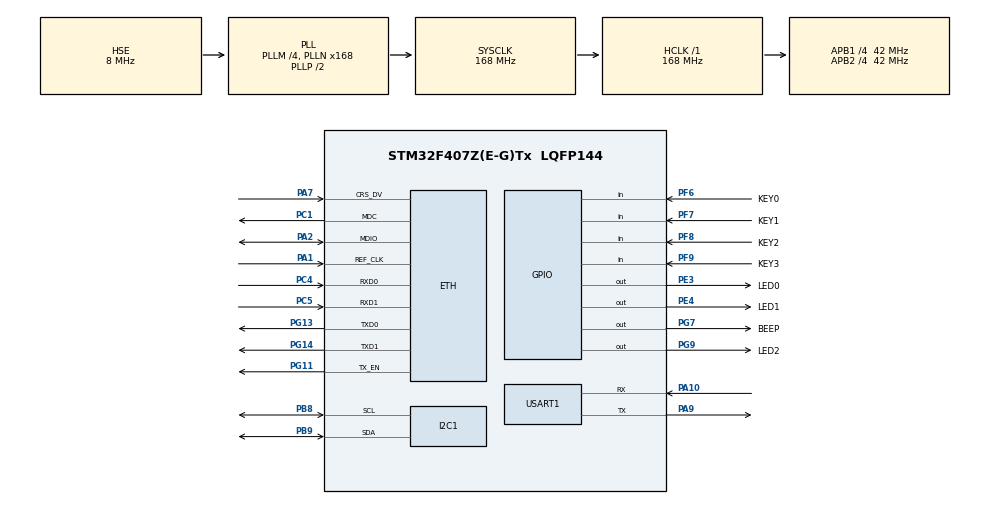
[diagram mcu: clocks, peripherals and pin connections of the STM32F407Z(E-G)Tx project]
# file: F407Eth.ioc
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Dma.Request0=USART1_RX
Dma.USART1_RX.0.Direction=DMA_PERIPH_TO_MEMORY
Dma.USART1_RX.0.FIFOMode=DMA_FIFOMODE_DISABLE
Dma.USART1_RX.0.Instance=DMA2_Stream2
Dma.USART1_RX.0.MemDataAlignment=DMA_MDATAALIGN_BYTE
Dma.USART1_RX.0.MemInc=DMA_MINC_ENABLE
Dma.USART1_RX.0.Mode=DMA_NORMAL
Dma.USART1_RX.0.PeriphDataAlignment=DMA_PDATAALIGN_BYTE
Dma.USART1_RX.0.PeriphInc=DMA_PINC_DISABLE
Dma.USART1_RX.0.Priority=DMA_PRIORITY_LOW
ETH.MediaInterface=ETH_MEDIA_INTERFACE_RMII
ETH.PHY_Name_RMII=userPHY
ETH.PHY_User_Name=DP83848
FREERTOS.Queues01=ethMsgQueue,16,ETH_MSG,0,Dynamic,NULL,NULL
FREERTOS.Tasks01=defaultTask,24,512,StartDefaultTask,Default,NULL,Dynamic,NULL,NULL;ethTask,8,512,StartEthTask,As weak,NULL,Dynamic,NULL,NULL;usart1Task,8,512,StartUsart1Task,As weak,NULL,Dynamic,NULL,NULL;serverTask,8,1024,StartServerTask,As weak,NULL,Dynamic,NULL,NULL
FREERTOS.configTOTAL_HEAP_SIZE=20480
LWIP.GATEWAY_ADDRESS=192.168.000.001
LWIP.IP_ADDRESS=192.168.000.111
LWIP.LWIP_DHCP=0
LWIP.LWIP_HTTPD=0
LWIP.MEMP_NUM_PBUF=40
LWIP.MEMP_NUM_TCP_SEG=800
LWIP.MEM_SIZE=15360
LWIP.NETMASK_ADDRESS=255.255.255.000
LWIP.PBUF_POOL_BUFSIZE=564
LWIP.PBUF_POOL_SIZE=40
LWIP.TCP_MSS=1024
LWIP.TCP_QUEUE_OOSEQ=0
LWIP.TCP_SND_BUF=15360
LWIP.TCP_SND_QUEUELEN=400
LWIP.TCP_WND=4096
LWIP.Version=v2.0.3_Cube
Mcu.Family=STM32F4
Mcu.Name=STM32F407Z(E-G)Tx
Mcu.Package=LQFP144
NVIC.DMA2_Stream2_IRQn=true\:5\:0\:false\:false\:true\:true\:false\:true
NVIC.ETH_IRQn=true\:5\:0\:false\:false\:true\:true\:true\:true
NVIC.PriorityGroup=NVIC_PRIORITYGROUP_4
NVIC.TIM1_UP_TIM10_IRQn=true\:0\:0\:false\:false\:true\:false\:false\:true
NVIC.TimeBase=TIM1_UP_TIM10_IRQn
NVIC.TimeBaseIP=TIM1
NVIC.USART1_IRQn=true\:5\:0\:false\:false\:true\:true\:true\:true
PA1.Mode=RMII
PA1.Signal=ETH_REF_CLK
PA10.Mode=Asynchronous
PA10.Signal=USART1_RX
PA13.Mode=JTAG_5_pins
PA13.Signal=SYS_JTMS-SWDIO
PA14.Mode=JTAG_5_pins
PA14.Signal=SYS_JTCK-SWCLK
PA15.Mode=JTAG_5_pins
PA15.Signal=SYS_JTDI
PA2.Mode=RMII
PA2.Signal=ETH_MDIO
PA7.Mode=RMII
PA7.Signal=ETH_CRS_DV
PA9.Mode=Asynchronous
PA9.Signal=USART1_TX
PB12.Signal=CAN2_RX
PB13.Signal=CAN2_TX
PB3.Mode=JTAG_5_pins
PB3.Signal=SYS_JTDO-SWO
PB4.Mode=JTAG_5_pins
PB4.Signal=SYS_JTRST
PB8.Mode=I2C
PB8.Signal=I2C1_SCL
PB9.Mode=I2C
PB9.Signal=I2C1_SDA
PC1.Mode=RMII
PC1.Signal=ETH_MDC
PC14-OSC32_IN.Mode=LSE-External-Oscillator
PC14-OSC32_IN.Signal=RCC_OSC32_IN
PC15-OSC32_OUT.Mode=LSE-External-Oscillator
PC15-OSC32_OUT.Signal=RCC_OSC32_OUT
PC4.Mode=RMII
PC4.Signal=ETH_RXD0
PC5.Mode=RMII
PC5.Signal=ETH_RXD1
PE3.GPIO_Label=LED0
PE3.GPIO_Speed=GPIO_SPEED_FREQ_HIGH
PE3.PinState=GPIO_PIN_SET
PE3.Signal=GPIO_Output
PE4.GPIO_Label=LED1
PE4.GPIO_Speed=GPIO_SPEED_FREQ_HIGH
PE4.PinState=GPIO_PIN_SET
PE4.Signal=GPIO_Output
PF6.GPIO_Label=KEY0
PF6.GPIO_PuPd=GPIO_PULLUP
PF6.Signal=GPIO_Input
PF7.GPIO_Label=KEY1
PF7.GPIO_PuPd=GPIO_PULLUP
PF7.Signal=GPIO_Input
PF8.GPIO_Label=KEY2
PF8.GPIO_PuPd=GPIO_PULLUP
PF8.Signal=GPIO_Input
PF9.GPIO_Label=KEY3
PF9.GPIO_PuPd=GPIO_PULLUP
PF9.Signal=GPIO_Input
PG11.Mode=RMII
PG11.Signal=ETH_TX_EN
PG13.Mode=RMII
PG13.Signal=ETH_TXD0
PG14.Mode=RMII
PG14.Signal=ETH_TXD1
PG7.GPIO_Label=BEEP
PG7.Signal=GPIO_Output
PG9.GPIO_Label=LED2
PG9.GPIO_Speed=GPIO_SPEED_FREQ_HIGH
PG9.PinState=GPIO_PIN_SET
PG9.Signal=GPIO_Output
PH0-OSC_IN.Mode=HSE-External-Oscillator
PH0-OSC_IN.Signal=RCC_OSC_IN
PH1-OSC_OUT.Mode=HSE-External-Oscillator
PH1-OSC_OUT.Signal=RCC_OSC_OUT
ProjectManager.HeapSize=0x200
ProjectManager.StackSize=0x400
ProjectManager.TargetToolchain=STM32CubeIDE
RCC.48MHZClocksFreq_Value=84000000
RCC.AHBFreq_Value=168000000
RCC.APB1CLKDivider=RCC_HCLK_DIV4
RCC.APB1Freq_Value=42000000
RCC.APB1TimFreq_Value=84000000
RCC.APB2CLKDivider=RCC_HCLK_DIV4
RCC.APB2Freq_Value=42000000
RCC.APB2TimFreq_Value=84000000
RCC.CortexFreq_Value=168000000
RCC.HCLKFreq_Value=168000000
RCC.HSE_VALUE=8000000
RCC.HSI_VALUE=16000000
RCC.PLLM=4
RCC.PLLN=168
RCC.PLLSourceVirtual=RCC_PLLSOURCE_HSE
RCC.SYSCLKFreq_VALUE=168000000
RCC.SYSCLKSource=RCC_SYSCLKSOURCE_PLLCLK
RCC.VCOOutputFreq_Value=336000000
USART1.VirtualMode=VM_ASYNC
VP_FREERTOS_VS_CMSIS_V2.Mode=CMSIS_V2
VP_LWIP_VS_Enabled.Mode=Enabled
VP_SYS_VS_tim1.Mode=TIM1
board=custom

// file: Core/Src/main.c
/* USER CODE BEGIN Header */
/**
  ******************************************************************************
  * @file           : main.c
  * @brief          : Main program body
  ******************************************************************************
  * @attention
  *
  * <h2><center>&copy; Copyright (c) 2020 STMicroelectronics.
  * All rights reserved.</center></h2>
  *
  * This software component is licensed by ST under BSD 3-Clause license,
  * the "License"; You may not use this file except in compliance with the
  * License. You may obtain a copy of the License at:
  *                        opensource.org/licenses/BSD-3-Clause
  *
  ******************************************************************************
  */
/* USER CODE END Header */

#include "main.h"
#include "cmsis_os.h"
#include "dma.h"
#include "i2c.h"
#include "lwip.h"
#include "usart.h"
#include "gpio.h"

/* USER CODE BEGIN Includes */
#include "TaskApp.h"

/* USER CODE END Includes */

void SystemClock_Config(void);
void MX_FREERTOS_Init(void);

int main(void)
{

  /* MCU Configuration--------------------------------------------------------*/

  /* Reset of all peripherals, Initializes the Flash interface and the Systick. */
  HAL_Init();

  /* Configure the system clock */
  SystemClock_Config();

  /* Initialize all configured peripherals */
  MX_GPIO_Init();
  MX_DMA_Init();
  MX_I2C1_Init();
  MX_USART1_UART_Init();
  MX_LWIP_Init();
  /* USER CODE BEGIN 2 */
  InitMyApp();
  /* USER CODE END 2 */
  /* Init scheduler */
  osKernelInitialize();

  /* Call init function for freertos objects (in freertos.c) */
  MX_FREERTOS_Init();

  /* Start scheduler */
  osKernelStart();

  /* We should never get here as control is now taken by the scheduler */

  /* Infinite loop */
  while (1)
  {

  }
}

void SystemClock_Config(void)
{
  RCC_OscInitTypeDef RCC_OscInitStruct = {0};
  RCC_ClkInitTypeDef RCC_ClkInitStruct = {0};

  /** Configure the main internal regulator output voltage
  */
  __HAL_RCC_PWR_CLK_ENABLE();
  __HAL_PWR_VOLTAGESCALING_CONFIG(PWR_REGULATOR_VOLTAGE_SCALE1);
  /** Initializes the CPU, AHB and APB busses clocks
  */
  RCC_OscInitStruct.OscillatorType = RCC_OSCILLATORTYPE_HSE;
  RCC_OscInitStruct.HSEState = RCC_HSE_ON;
  RCC_OscInitStruct.PLL.PLLState = RCC_PLL_ON;
  RCC_OscInitStruct.PLL.PLLSource = RCC_PLLSOURCE_HSE;
  RCC_OscInitStruct.PLL.PLLM = 4;
  RCC_OscInitStruct.PLL.PLLN = 168;
  RCC_OscInitStruct.PLL.PLLP = RCC_PLLP_DIV2;
  RCC_OscInitStruct.PLL.PLLQ = 4;
  if (HAL_RCC_OscConfig(&RCC_OscInitStruct) != HAL_OK)
  {
    Error_Handler();
  }
  /** Initializes the CPU, AHB and APB busses clocks
  */
  RCC_ClkInitStruct.ClockType = RCC_CLOCKTYPE_HCLK|RCC_CLOCKTYPE_SYSCLK
                              |RCC_CLOCKTYPE_PCLK1|RCC_CLOCKTYPE_PCLK2;
  RCC_ClkInitStruct.SYSCLKSource = RCC_SYSCLKSOURCE_PLLCLK;
  RCC_ClkInitStruct.AHBCLKDivider = RCC_SYSCLK_DIV1;
  RCC_ClkInitStruct.APB1CLKDivider = RCC_HCLK_DIV4;
  RCC_ClkInitStruct.APB2CLKDivider = RCC_HCLK_DIV4;

  if (HAL_RCC_ClockConfig(&RCC_ClkInitStruct, FLASH_LATENCY_5) != HAL_OK)
  {
    Error_Handler();
  }
}

void HAL_TIM_PeriodElapsedCallback(TIM_HandleTypeDef *htim)
{
  if (htim->Instance == TIM1) {
    HAL_IncTick();
  }
}

void Error_Handler(void)
{
}

/************************ (C) COPYRIGHT STMicroelectronics *****END OF FILE****/

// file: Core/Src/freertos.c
/* USER CODE BEGIN Header */
/**
  ******************************************************************************
  * File Name          : freertos.c
  * Description        : Code for freertos applications
  ******************************************************************************
  * @attention
  *
  * <h2><center>&copy; Copyright (c) 2020 STMicroelectronics.
  * All rights reserved.</center></h2>
  *
  * This software component is licensed by ST under Ultimate Liberty license
  * SLA0044, the "License"; You may not use this file except in compliance with
  * the License. You may obtain a copy of the License at:
  *                             www.st.com/SLA0044
  *
  ******************************************************************************
  */
/* USER CODE END Header */

#include "FreeRTOS.h"
#include "task.h"
#include "main.h"
#include "cmsis_os.h"

/* USER CODE BEGIN Includes */
#include "TaskApp.h"

/* USER CODE END Includes */

/* Definitions for defaultTask */
osThreadId_t defaultTaskHandle;
const osThreadAttr_t defaultTask_attributes = {
  .name = "defaultTask",
  .priority = (osPriority_t) osPriorityNormal,
  .stack_size = 512
};
/* Definitions for ethTask */
osThreadId_t ethTaskHandle;
const osThreadAttr_t ethTask_attributes = {
  .name = "ethTask",
  .priority = (osPriority_t) osPriorityLow,
  .stack_size = 512
};
/* Definitions for usart1Task */
osThreadId_t usart1TaskHandle;
const osThreadAttr_t usart1Task_attributes = {
  .name = "usart1Task",
  .priority = (osPriority_t) osPriorityLow,
  .stack_size = 512
};
/* Definitions for serverTask */
osThreadId_t serverTaskHandle;
const osThreadAttr_t serverTask_attributes = {
  .name = "serverTask",
  .priority = (osPriority_t) osPriorityLow,
  .stack_size = 1024
};
/* Definitions for ethMsgQueue */
osMessageQueueId_t ethMsgQueueHandle;
const osMessageQueueAttr_t ethMsgQueue_attributes = {
  .name = "ethMsgQueue"
};

/* USER CODE BEGIN FunctionPrototypes */
extern uint32_t RunTime;

/* USER CODE END FunctionPrototypes */

void StartDefaultTask(void *argument);
void StartEthTask(void *argument);
void StartUsart1Task(void *argument);
void StartServerTask(void *argument);

extern void MX_LWIP_Init(void);
void MX_FREERTOS_Init(void); /* (MISRA C 2004 rule 8.1) */

void MX_FREERTOS_Init(void) {

  /* Create the queue(s) */
  /* creation of ethMsgQueue */
  ethMsgQueueHandle = osMessageQueueNew (16, sizeof(ETH_MSG), &ethMsgQueue_attributes);

  /* Create the thread(s) */
  /* creation of defaultTask */
  defaultTaskHandle = osThreadNew(StartDefaultTask, NULL, &defaultTask_attributes);

  /* creation of ethTask */
  ethTaskHandle = osThreadNew(StartEthTask, NULL, &ethTask_attributes);

  /* creation of usart1Task */
  usart1TaskHandle = osThreadNew(StartUsart1Task, NULL, &usart1Task_attributes);

  /* creation of serverTask */
  serverTaskHandle = osThreadNew(StartServerTask, NULL, &serverTask_attributes);

}

void StartDefaultTask(void *argument)
{
  /* USER CODE BEGIN StartDefaultTask */
  //tcp_socket_svr_init();
  /* Infinite loop */
  for(;;)
  {
	LED0_T;
    osDelay(100);
	RunTime++;
  }
  /* USER CODE END StartDefaultTask */
}

__weak void StartEthTask(void *argument)
{
  /* USER CODE BEGIN StartEthTask */
  /* Infinite loop */
  for(;;)
  {
    osDelay(10);
  }
  /* USER CODE END StartEthTask */
}

__weak void StartUsart1Task(void *argument)
{
  for(;;)
  {
    osDelay(1);
  }
}

__weak void StartServerTask(void *argument)
{
  for(;;)
  {
    osDelay(1);
  }
}

/************************ (C) COPYRIGHT STMicroelectronics *****END OF FILE****/
